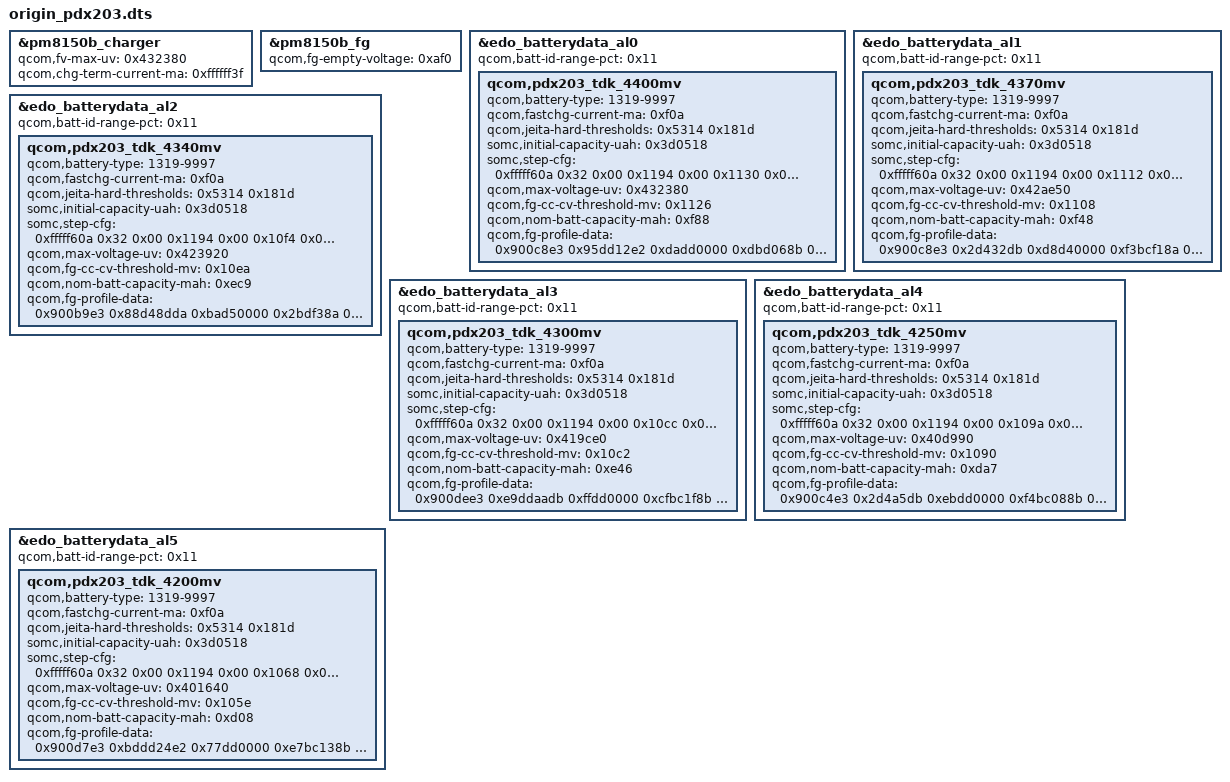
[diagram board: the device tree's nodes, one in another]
/dts-v1/;
/plugin/;

&pm8150b_charger {
	qcom,fv-max-uv = <0x432380>;
	qcom,chg-term-current-ma = <0xffffff3f>;
};
&pm8150b_fg {
	qcom,fg-empty-voltage = <0xaf0>;
};
&edo_batterydata_al0 {
	qcom,batt-id-range-pct = <0x11>;
	qcom,pdx203_tdk_4400mv {
		qcom,battery-type = "1319-9997";
		qcom,fastchg-current-ma = <0xf0a>;
		qcom,jeita-hard-thresholds = <0x5314 0x181d>;
		somc,initial-capacity-uah = <0x3d0518>;
		somc,step-cfg = <0xfffff60a 0x32 0x00 0x1194 0x00 0x1130 0x01 0x32 0x78 0x00 0x1194 0x2ee 0x1130 0x02 0x78 0xc8 0x00 0x1004 0x8fc 0x1130 0x03 0x78 0xc8 0x1004 0x1068 0x76c 0x1130 0x03 0x78 0xc8 0x1068 0x10cc 0x5dc 0x1130 0x03 0x78 0xc8 0x10cc 0x1194 0x47e 0x1130 0x03 0xc8 0x1c2 0x00 0x1036 0xf0a 0x1130 0x03 0xc8 0x1c2 0x1036 0x1068 0xb22 0x1130 0x03 0xc8 0x1c2 0x1068 0x10cc 0x76c 0x1130 0x03 0xc8 0x1c2 0x10cc 0x1194 0x47e 0x1130 0x03 0x1c2 0x226 0x00 0x1194 0x47e 0x1068 0x04 0x226 0x9f6 0x00 0x1194 0x00 0x1068 0x05>;
		qcom,max-voltage-uv = <0x432380>;
		qcom,fg-cc-cv-threshold-mv = <0x1126>;
		qcom,nom-batt-capacity-mah = <0xf88>;
		qcom,fg-profile-data = <0x900c8e3 0x95dd12e2 0xdadd0000 0xdbd068b 0xfa87b68b 0xad9d5b80 0x1d0049fa 0xac1277fd 0x13bdce07 0x3200f3ea 0xb407eacb 0x2c0b14e5 0x62c49e02 0xfef314d3 0x60004b00 0x4b004700 0x29003400 0x3b004100 0x41004100 0x3f006000 0x34004200 0x4c004400 0x3e009300 0x5e644d00 0x41004200 0x60f05000 0x4e007510 0x59104c00 0x9e286d48 0x58604b0d 0x4c00d800 0x141f4006 0x9a039504 0x931c3a0b 0x9a0db522 0x42181942 0x885d0402 0x6010af1e 0xbdfe0503 0x54f7d21c 0x4d02f904 0x84037018 0x5523e344 0x1526411 0xeb1eefe4 0x74cb63cc 0xda1caac1 0xda04a4bb 0x5a183193 0x2b857293 0x7c900980 0x89f37c05 0x18fbbb04 0xf8b6d4 0x3bdaf007 0x68d398bd 0x131018d8 0xf1cd7c03 0xed04c500 0xce073200 0xd102b502 0xb3058a01 0x3302cf04 0x8c03c203 0xd6024600 0x3d004d00 0x50645400 0x51004f08 0x54005200 0x54006808 0x37084500 0x56285448 0x6060720c 0x49005b00 0x5d086000 0x52004300 0x4b105510 0x4e006328 0x7b484560 0x590c6200 0x62f84700 0xd8003620 0x7205480a 0x960ef71c 0xe3223344 0xd45b7e18 0x3d023d05 0x5902720f 0x3f0a9e1f 0xcd053602 0xa206d01c 0xef02fb05 0x34027b18 0x2c025305 0x46026900 0xf21efd04 0x85030607 0xdb1c5f02 0xf7047703 0xa8186703 0x9f045002 0x67000b01 0xc000fa00 0x9f0f0000>;
	};
};
&edo_batterydata_al1 {
	qcom,batt-id-range-pct = <0x11>;
	qcom,pdx203_tdk_4370mv {
		qcom,battery-type = "1319-9997";
		qcom,fastchg-current-ma = <0xf0a>;
		qcom,jeita-hard-thresholds = <0x5314 0x181d>;
		somc,initial-capacity-uah = <0x3d0518>;
		somc,step-cfg = <0xfffff60a 0x32 0x00 0x1194 0x00 0x1112 0x01 0x32 0x78 0x00 0x1194 0x2ee 0x1112 0x02 0x78 0xc8 0x00 0x1004 0x8fc 0x1112 0x03 0x78 0xc8 0x1004 0x1068 0x6a4 0x1112 0x03 0x78 0xc8 0x1068 0x10cc 0x5dc 0x1112 0x03 0x78 0xc8 0x10cc 0x1194 0x47e 0x1112 0x03 0xc8 0x1c2 0x00 0x1036 0xd7a 0x1112 0x03 0xc8 0x1c2 0x1036 0x1068 0xa8c 0x1112 0x03 0xc8 0x1c2 0x1068 0x10cc 0x76c 0x1112 0x03 0xc8 0x1c2 0x10cc 0x1194 0x47e 0x1112 0x03 0x1c2 0x226 0x00 0x1194 0x47e 0x1068 0x04 0x226 0x9f6 0x00 0x1194 0x00 0x1068 0x05>;
		qcom,max-voltage-uv = <0x42ae50>;
		qcom,fg-cc-cv-threshold-mv = <0x1108>;
		qcom,nom-batt-capacity-mah = <0xf48>;
		qcom,fg-profile-data = <0x900c8e3 0x2d432db 0xd8d40000 0xf3bcf18a 0xfb87248b 0x2c9d7280 0x2200b601 0x95129406 0x47e2ce07 0x32006feb 0x5bed0dc4 0xb60bebe4 0xcdcd56eb 0x4901dbd2 0x60004d00 0x47004600 0x2d003500 0x3b003d00 0x41004100 0x40006000 0x2c003c00 0x46004000 0x39008800 0x5a644900 0x3d003900 0x60f84e00 0x4b006d10 0x58104900 0xa6286c48 0x5760490c 0x4700d8f8 0x371f1206 0xd5f3ff05 0x7b1c7c0b 0x640de422 0x2185942 0x55a802 0x6111cf1e 0x2bfd3703 0xcafcd61c 0x3bfa1f05 0x4803b018 0xfc226145 0x2e536811 0x2c1f57e4 0xd7c3c3b5 0xd81c53bb 0xdb0489bb 0x39184793 0x17858a9b 0x80980980 0xa2eb8d04 0x72fb84f2 0xf889dc 0x4fe2f0ff 0x84e277cd 0x1c101900 0xf5dde303 0xeb040903 0xce073200 0xfb023702 0xbe048902 0x34045902 0xa2039901 0x49054400 0x3c004d00 0x51645500 0x52005100 0x53005100 0x53005e08 0x34084400 0x56285348 0x5e606f0d 0x48005900 0x61086600 0x6f004100 0x4a085508 0x4e006128 0x7a484560 0x560d6100 0x61f84608 0xd8f80420 0xbf05fd0b 0xd90ef91c 0xd3225844 0x9e5b8718 0x25027605 0x1402730f 0x3f0a4220 0x1305b402 0x2706d91c 0xb9027904 0xa9038318 0x17028605 0x6027400 0x431f3104 0xd026905 0xd81c5702 0x16053903 0xa6186503 0xa1045002 0x6d000301 0xc000fa00 0x550f0000>;
	};
};
&edo_batterydata_al2 {
	qcom,batt-id-range-pct = <0x11>;
	qcom,pdx203_tdk_4340mv {
		qcom,battery-type = "1319-9997";
		qcom,fastchg-current-ma = <0xf0a>;
		qcom,jeita-hard-thresholds = <0x5314 0x181d>;
		somc,initial-capacity-uah = <0x3d0518>;
		somc,step-cfg = <0xfffff60a 0x32 0x00 0x1194 0x00 0x10f4 0x01 0x32 0x78 0x00 0x1194 0x2ee 0x10f4 0x02 0x78 0xc8 0x00 0x1004 0x8fc 0x10f4 0x03 0x78 0xc8 0x1004 0x1068 0x6a4 0x10f4 0x03 0x78 0xc8 0x1068 0x10cc 0x5dc 0x10f4 0x03 0x78 0xc8 0x10cc 0x1194 0x47e 0x10f4 0x03 0xc8 0x1c2 0x00 0x1036 0xd7a 0x10f4 0x03 0xc8 0x1c2 0x1036 0x1068 0xa8c 0x10f4 0x03 0xc8 0x1c2 0x1068 0x10cc 0x76c 0x10f4 0x03 0xc8 0x1c2 0x10cc 0x1194 0x47e 0x10f4 0x03 0x1c2 0x226 0x00 0x1194 0x47e 0x1068 0x04 0x226 0x9f6 0x00 0x1194 0x00 0x1068 0x05>;
		qcom,max-voltage-uv = <0x423920>;
		qcom,fg-cc-cv-threshold-mv = <0x10ea>;
		qcom,nom-batt-capacity-mah = <0xec9>;
		qcom,fg-profile-data = <0x900b9e3 0x88d48dda 0xbad50000 0x2bdf38a 0xfb87f59a 0x49c5580 0x1e003f01 0x6412dffd 0x96e4ce07 0x320015eb 0x72ed43d2 0xaf0b9de5 0x13c4c10c 0x47dacdd2 0x60004d00 0x4c004900 0x2c003500 0x3b004100 0x45004000 0x3e006000 0x33004200 0x4c004600 0x3d008b00 0x62644e00 0x40003e08 0x60005000 0x4b006c08 0x5b084900 0xa7206e40 0x59584a0e 0x4400d800 0xac1f930d 0x4002a7fe 0xae1cc002 0x4804ea23 0x6718b743 0x1154e102 0x6f113421 0x1afc3d03 0xc4f5f71c 0x29030805 0x310b4418 0x6b23de44 0xec539411 0xda1e0fe5 0x44c377bc 0xc81cd5b1 0x3f040cba 0x49183393 0x2b85719b 0x78980980 0x98eb6f04 0x2802eff3 0xf88dd4 0x62e2ee07 0xfce330c5 0xfc171800 0x49dda503 0x5c06a103 0xce073200 0xf902d902 0xf4050c03 0x4b04a202 0x67025d01 0xfc054400 0x3c004d00 0x50645400 0x52005000 0x53f05300 0x53004f10 0x37104300 0x55285348 0x5e606f0c 0x4a005200 0x5c085c00 0x4d004100 0x49105610 0x4f005f28 0x7a484760 0x520c5c00 0x5c004108 0xd8f8a71f 0x2b06540b 0x930ce41c 0xe23f345 0xe5a7b18 0x37024705 0x51026c10 0x3f0aa91f 0xc6052b02 0x9f06bb1c 0x2203d105 0x50027818 0x25025e05 0x3d026900 0xac1faa05 0x5102e104 0xe11c2202 0x8d059c02 0xab184b03 0xd3041c02 0x78000301 0xc000fa00 0xd0f0000>;
	};
};
&edo_batterydata_al3 {
	qcom,batt-id-range-pct = <0x11>;
	qcom,pdx203_tdk_4300mv {
		qcom,battery-type = "1319-9997";
		qcom,fastchg-current-ma = <0xf0a>;
		qcom,jeita-hard-thresholds = <0x5314 0x181d>;
		somc,initial-capacity-uah = <0x3d0518>;
		somc,step-cfg = <0xfffff60a 0x32 0x00 0x1194 0x00 0x10cc 0x01 0x32 0x78 0x00 0x1194 0x2ee 0x10cc 0x02 0x78 0xc8 0x00 0x1004 0x8fc 0x10cc 0x03 0x78 0xc8 0x1004 0x1068 0x5dc 0x10cc 0x03 0x78 0xc8 0x1068 0x1194 0x546 0x10cc 0x03 0xc8 0x1c2 0x00 0x1036 0xbea 0x10cc 0x03 0xc8 0x1c2 0x1036 0x1068 0x8fc 0x10cc 0x03 0xc8 0x1c2 0x1068 0x1194 0x5dc 0x10cc 0x03 0x1c2 0x226 0x00 0x1194 0x47e 0x1068 0x04 0x226 0x9f6 0x00 0x1194 0x00 0x1068 0x05>;
		qcom,max-voltage-uv = <0x419ce0>;
		qcom,fg-cc-cv-threshold-mv = <0x10c2>;
		qcom,nom-batt-capacity-mah = <0xe46>;
		qcom,fg-profile-data = <0x900dee3 0xe9ddaadb 0xffdd0000 0xcfbc1f8b 0xfb879082 0xa1946680 0x200039fb 0x631207f4 0x71edce07 0x32002feb 0x45edd6d2 0x830b9de5 0x4dc4cf04 0xac003dd2 0x60004d00 0x4c004b00 0x33003500 0x39004200 0x4d004100 0x3b006000 0x33004300 0x49004600 0x3b006400 0x63645000 0x40003708 0x60f85000 0x4c005e08 0x5f084800 0x88207348 0x58584a0e 0x4200d808 0xe91f550d 0x5d020f05 0x9e1cd402 0x3f04ce23 0x8018b643 0xf8551403 0x73118d22 0x6905fe03 0x1f05fa1c 0x82f94705 0xd5023c18 0x59230545 0xa153a013 0x831fe3e5 0xfdc3cbb6 0xde1c0dbb 0x5005e1ba 0x5b18f292 0x9885b39a 0x8b980980 0xb803a004 0xa0fa61f2 0xf84bdc 0x95e2ed07 0xddeacdd5 0xf101800 0xd0e7a303 0xcf047903 0xce073200 0x29034903 0x1204ae02 0x94044a02 0x2002cb02 0xa7044600 0x3c004f00 0x52645500 0x55f85300 0x53f05500 0x56004c08 0x37084200 0x56285448 0x5d606e0d 0x52004e00 0x5a086400 0x54004200 0x47085508 0x52005c20 0x78485f58 0x4e0e5d00 0x63f84d00 0xd8f8781f 0xe704cc0a 0x750de11c 0x8230044 0xef538318 0x1d028105 0xa026c10 0x3f0a9720 0xc604d202 0x6d71c 0xa002bb04 0x3a039418 0xd203e705 0x30037b00 0x621f0904 0xff036d05 0xd11c5202 0x3105f102 0xb0182603 0x1205c503 0x72000801 0xc000fa00 0x8a0e0000>;
	};
};
&edo_batterydata_al4 {
	qcom,batt-id-range-pct = <0x11>;
	qcom,pdx203_tdk_4250mv {
		qcom,battery-type = "1319-9997";
		qcom,fastchg-current-ma = <0xf0a>;
		qcom,jeita-hard-thresholds = <0x5314 0x181d>;
		somc,initial-capacity-uah = <0x3d0518>;
		somc,step-cfg = <0xfffff60a 0x32 0x00 0x1194 0x00 0x109a 0x01 0x32 0x78 0x00 0x1194 0x2ee 0x109a 0x02 0x78 0xc8 0x00 0x1004 0x76c 0x109a 0x03 0x78 0xc8 0x1004 0x1068 0x546 0x109a 0x03 0x78 0xc8 0x1068 0x1194 0x47e 0x109a 0x03 0xc8 0x1c2 0x00 0x1036 0xa8c 0x109a 0x03 0xc8 0x1c2 0x1036 0x1068 0x76c 0x109a 0x03 0xc8 0x1c2 0x1068 0x1194 0x5dc 0x109a 0x03 0x1c2 0x226 0x00 0x1194 0x47e 0x1068 0x04 0x226 0x9f6 0x00 0x1194 0x00 0x1068 0x05>;
		qcom,max-voltage-uv = <0x40d990>;
		qcom,fg-cc-cv-threshold-mv = <0x1090>;
		qcom,nom-batt-capacity-mah = <0xda7>;
		qcom,fg-profile-data = <0x900c4e3 0x2d4a5db 0xebdd0000 0xf4bc088b 0xfa878c8d 0x17957a80 0x23002402 0x5b127006 0x25eace07 0x3200fdeb 0xeeecefc2 0x66121be5 0x61cdfa0d 0x19fafbcb 0x60004100 0x40004000 0x3b003100 0x38004800 0x42003f00 0x41006000 0x26003400 0x41004200 0x37003b00 0x59644400 0x39003308 0x60005000 0x4c004908 0x64084800 0x4e207340 0x5658470e 0x4000d8f8 0x39201805 0x6cf27a06 0xa01cab0a 0xab0c3323 0x7c189843 0x3254c902 0x7c121f1f 0xb10c3113 0x8f04d21c 0xb02a405 0x66fa6e18 0xf236145 0x18537713 0x91249ce4 0x62c28ea4 0xe61c48b9 0x3806b1bb 0x5c18f392 0x9585b79a 0xb6980980 0xa2bb250d 0xa20529f3 0x7de4 0x6f02ee07 0xefe23abd 0x1f0018e8 0xdec20002 0x60064903 0xce073200 0x9c012302 0xbc07e602 0x85034004 0x6b035604 0x91054500 0x3c005000 0x51645500 0x56005200 0x52e85500 0x53004408 0x36084000 0x55205248 0x5a58690e 0x70004900 0x5c086300 0x4c004300 0x46085408 0x55005920 0x75407358 0x480f5a00 0x62005208 0xd8f8861f 0x8e065a0a 0xd50cf31c 0xa422db44 0xda529318 0xeb03d905 0x45037911 0x3f0a6821 0x43e03 0xa105e81c 0x54024f05 0x8702af18 0x6b039b04 0x54028800 0x2d203e05 0x6e02a504 0xdf1c0002 0xde051402 0xb818f902 0x62052e03 0x85000701 0xc000fa00 0xe50d0000>;
	};
};
&edo_batterydata_al5 {
	qcom,batt-id-range-pct = <0x11>;
	qcom,pdx203_tdk_4200mv {
		qcom,battery-type = "1319-9997";
		qcom,fastchg-current-ma = <0xf0a>;
		qcom,jeita-hard-thresholds = <0x5314 0x181d>;
		somc,initial-capacity-uah = <0x3d0518>;
		somc,step-cfg = <0xfffff60a 0x32 0x00 0x1194 0x00 0x1068 0x01 0x32 0x78 0x00 0x1194 0x2ee 0x1068 0x02 0x78 0xc8 0x00 0x1004 0x76c 0x1068 0x03 0x78 0xc8 0x1004 0x1194 0x546 0x1068 0x03 0xc8 0x1c2 0x00 0x1036 0xa8c 0x1068 0x03 0xc8 0x1c2 0x1036 0x1194 0x76c 0x1068 0x03 0x1c2 0x226 0x00 0x1194 0x47e 0x1068 0x04 0x226 0x9f6 0x00 0x1194 0x00 0x1068 0x05>;
		qcom,max-voltage-uv = <0x401640>;
		qcom,fg-cc-cv-threshold-mv = <0x105e>;
		qcom,nom-batt-capacity-mah = <0xd08>;
		qcom,fg-profile-data = <0x900d7e3 0xbddd24e2 0x77dd0000 0xe7bc138b 0xfa879195 0xe3958180 0x25004902 0x6f126506 0x4e00ce07 0x320016f2 0xa7ec73c3 0x2b129bdc 0xd4cdeff5 0x53fa14ca 0x60004200 0x42004100 0x41002700 0x35004100 0x3b004400 0x2e006000 0x27003600 0x42004500 0x39003400 0x5d644300 0x39003208 0x60005500 0x4e004908 0x6d084e00 0x44207b40 0x5658470f 0x4100d800 0x4e202605 0x3d02ad06 0x9b1c9302 0xf004cb22 0x8b186943 0x83547802 0x8313d71f 0xa705f60b 0xca06d81c 0xdf010d04 0xbc037718 0xe222a945 0x9e528814 0x73200be5 0x63c26bce 0xd11c88c1 0x620579ba 0x5518c992 0xd7854c92 0x9b800980 0x9d037304 0x4c02ff04 0xf873e4 0x78eaeeef 0x310475c7 0x60101ac8 0x10e0c803 0x7a06ca00 0xce073200 0x6903b803 0x7704a402 0x8700d805 0x74026905 0xbb054600 0x3b004f00 0x51645400 0x57e854e8 0x55e85400 0x53004508 0x35083d00 0x55205048 0x5858650e 0x75004600 0x56086b00 0x5a003d00 0x40085108 0x53005020 0x6b407c58 0x400f5000 0x63005900 0xd8f89d1e 0xe5054d0b 0xe90bdd1c 0xcf229f44 0xb538118 0xe903db05 0x42036d12 0x3f0ac220 0xd0049202 0x3a06d31c 0x78022505 0x9502a518 0x6503a304 0x4e028500 0x5e1f3006 0x6003f105 0xca1c3602 0x81056402 0xb918da02 0x9305dd02 0x7b000b01 0xc000fa00 0x290d0000>;
	};
};
